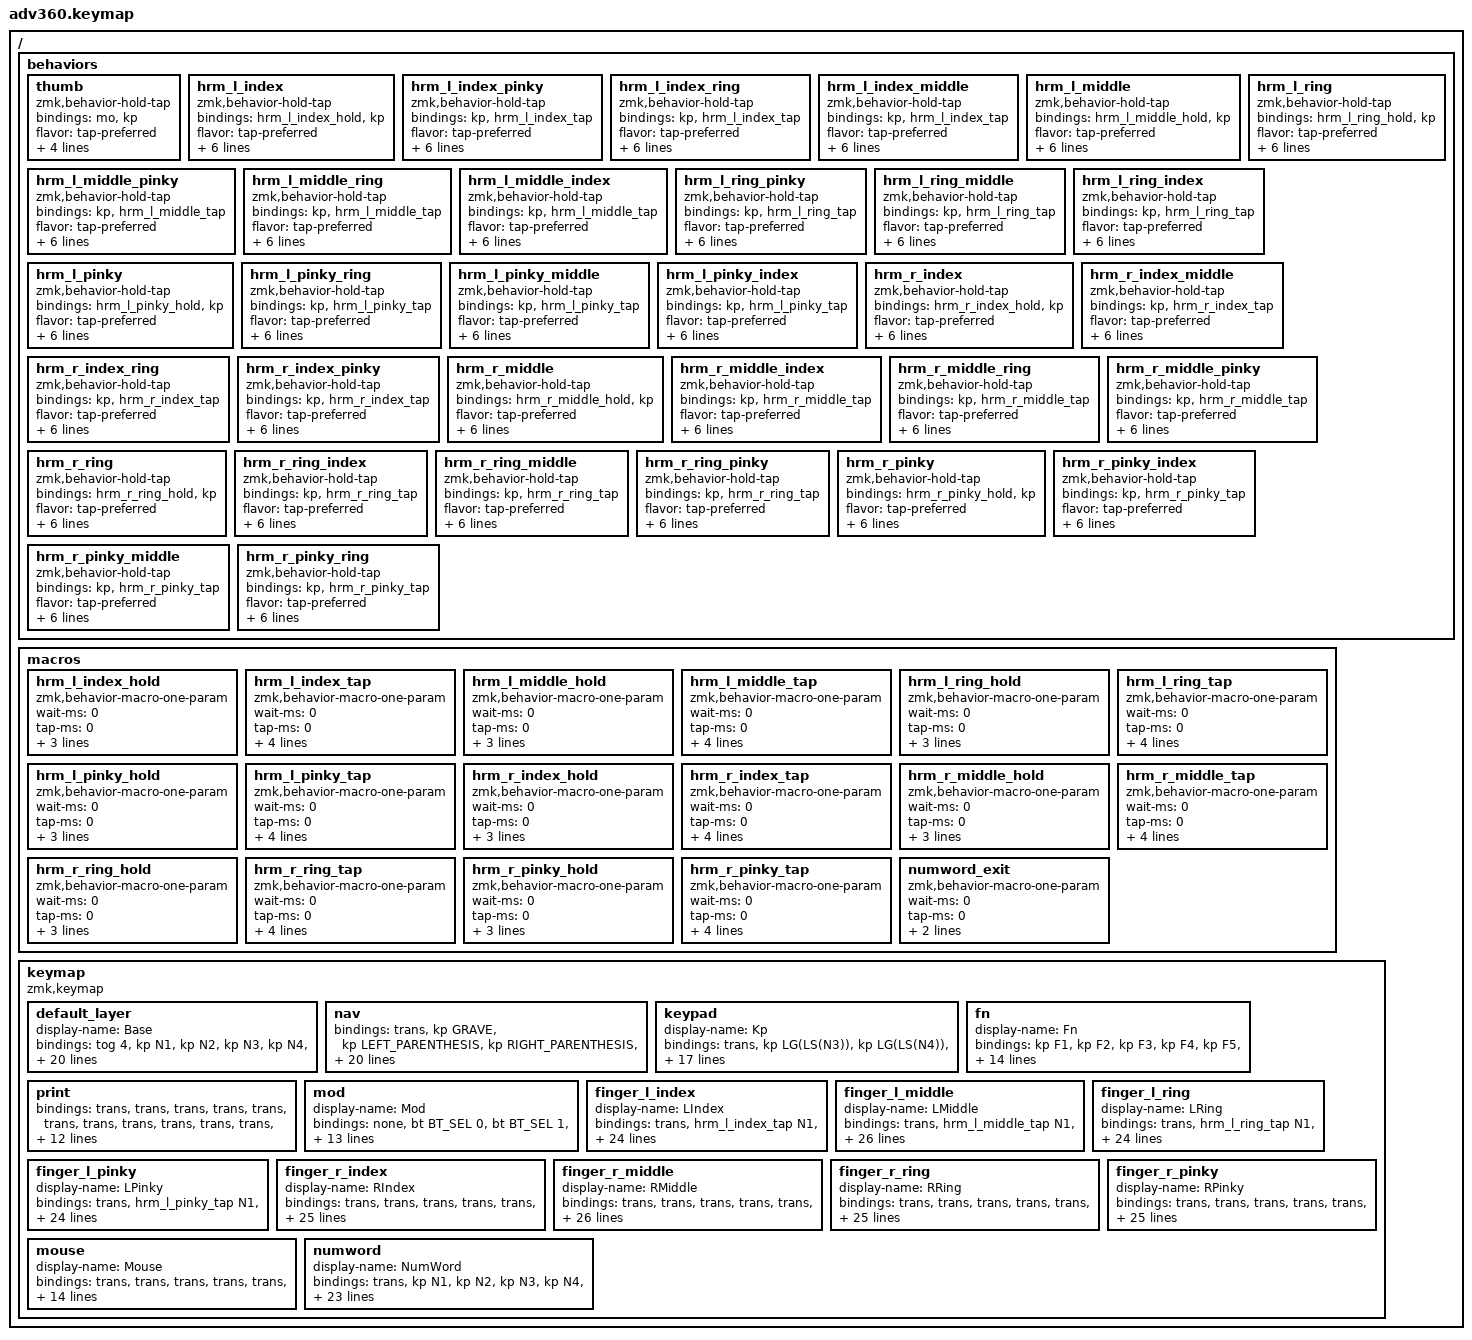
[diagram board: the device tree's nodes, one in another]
#include <dt-bindings/zmk/stp.h>
#include <behaviors.dtsi>
#include <dt-bindings/zmk/backlight.h>
#include <dt-bindings/zmk/bt.h>
#include <dt-bindings/zmk/keys.h>
#include <dt-bindings/zmk/pointing.h>
#include <dt-bindings/zmk/rgb.h>

/ {
    behaviors {
        #include "macros.dtsi"
      #include "version.dtsi"

        thumb: thumb {
            compatible = "zmk,behavior-hold-tap";
            #binding-cells = <2>;
            bindings = <&mo>, <&kp>;
            flavor = "tap-preferred";
            tapping-term-ms = <200>;
            quick-tap-ms = <300>;
            require-prior-idle-ms = <150>;
            retro-tap;
        };

        hrm_l_index: hrm_l_index {
            compatible = "zmk,behavior-hold-tap";
            #binding-cells = <2>;
            bindings = <&hrm_l_index_hold>, <&kp>;
            flavor = "tap-preferred";
            tapping-term-ms = <180>;
            quick-tap-ms = <300>;
            require-prior-idle-ms = <150>;
            hold-trigger-on-release;
            hold-trigger-key-positions = <7 8 9 10 11 12 13 21 22 23 24 25 26 27 37 38 39 40 41 42 43 44 45 53 54 55 56 57 58 59 68 69 70 71 72 73 74 75>;
        };

        hrm_l_index_pinky: hrm_l_index_pinky {
            compatible = "zmk,behavior-hold-tap";
            #binding-cells = <2>;
            bindings = <&kp>, <&hrm_l_index_tap>;
            flavor = "tap-preferred";
            tapping-term-ms = <180>;
            quick-tap-ms = <300>;
            require-prior-idle-ms = <150>;
            hold-trigger-on-release;
            hold-trigger-key-positions = <7 8 9 10 11 12 13 21 22 23 24 25 26 27 37 38 39 40 41 42 43 44 45 53 54 55 56 57 58 59 68 69 70 71 72 73 74 75>;
        };

        hrm_l_index_ring: hrm_l_index_ring {
            compatible = "zmk,behavior-hold-tap";
            #binding-cells = <2>;
            bindings = <&kp>, <&hrm_l_index_tap>;
            flavor = "tap-preferred";
            tapping-term-ms = <180>;
            quick-tap-ms = <300>;
            require-prior-idle-ms = <150>;
            hold-trigger-on-release;
            hold-trigger-key-positions = <7 8 9 10 11 12 13 21 22 23 24 25 26 27 37 38 39 40 41 42 43 44 45 53 54 55 56 57 58 59 68 69 70 71 72 73 74 75>;
        };

        hrm_l_index_middle: hrm_l_index_middle {
            compatible = "zmk,behavior-hold-tap";
            #binding-cells = <2>;
            bindings = <&kp>, <&hrm_l_index_tap>;
            flavor = "tap-preferred";
            tapping-term-ms = <180>;
            quick-tap-ms = <300>;
            require-prior-idle-ms = <150>;
            hold-trigger-on-release;
            hold-trigger-key-positions = <7 8 9 10 11 12 13 21 22 23 24 25 26 27 37 38 39 40 41 42 43 44 45 53 54 55 56 57 58 59 68 69 70 71 72 73 74 75>;
        };

        hrm_l_middle: hrm_l_middle {
            compatible = "zmk,behavior-hold-tap";
            #binding-cells = <2>;
            bindings = <&hrm_l_middle_hold>, <&kp>;
            flavor = "tap-preferred";
            tapping-term-ms = <210>;
            quick-tap-ms = <300>;
            require-prior-idle-ms = <150>;
            hold-trigger-on-release;
            hold-trigger-key-positions = <7 8 9 10 11 12 13 21 22 23 24 25 26 27 37 38 39 40 41 42 43 44 45 53 54 55 56 57 58 59 68 69 70 71 72 73 74 75>;
        };

        hrm_l_middle_pinky: hrm_l_middle_pinky {
            compatible = "zmk,behavior-hold-tap";
            #binding-cells = <2>;
            bindings = <&kp>, <&hrm_l_middle_tap>;
            flavor = "tap-preferred";
            tapping-term-ms = <210>;
            quick-tap-ms = <300>;
            require-prior-idle-ms = <150>;
            hold-trigger-on-release;
            hold-trigger-key-positions = <7 8 9 10 11 12 13 21 22 23 24 25 26 27 37 38 39 40 41 42 43 44 45 53 54 55 56 57 58 59 68 69 70 71 72 73 74 75>;
        };

        hrm_l_middle_ring: hrm_l_middle_ring {
            compatible = "zmk,behavior-hold-tap";
            #binding-cells = <2>;
            bindings = <&kp>, <&hrm_l_middle_tap>;
            flavor = "tap-preferred";
            tapping-term-ms = <210>;
            quick-tap-ms = <300>;
            require-prior-idle-ms = <150>;
            hold-trigger-on-release;
            hold-trigger-key-positions = <7 8 9 10 11 12 13 21 22 23 24 25 26 27 37 38 39 40 41 42 43 44 45 53 54 55 56 57 58 59 68 69 70 71 72 73 74 75>;
        };

        hrm_l_middle_index: hrm_l_middle_index {
            compatible = "zmk,behavior-hold-tap";
            #binding-cells = <2>;
            bindings = <&kp>, <&hrm_l_middle_tap>;
            flavor = "tap-preferred";
            tapping-term-ms = <210>;
            quick-tap-ms = <300>;
            require-prior-idle-ms = <150>;
            hold-trigger-on-release;
            hold-trigger-key-positions = <7 8 9 10 11 12 13 21 22 23 24 25 26 27 37 38 39 40 41 42 43 44 45 53 54 55 56 57 58 59 68 69 70 71 72 73 74 75>;
        };

        hrm_l_ring: hrm_l_ring {
            compatible = "zmk,behavior-hold-tap";
            #binding-cells = <2>;
            bindings = <&hrm_l_ring_hold>, <&kp>;
            flavor = "tap-preferred";
            tapping-term-ms = <240>;
            quick-tap-ms = <300>;
            require-prior-idle-ms = <150>;
            hold-trigger-on-release;
            hold-trigger-key-positions = <7 8 9 10 11 12 13 21 22 23 24 25 26 27 37 38 39 40 41 42 43 44 45 53 54 55 56 57 58 59 68 69 70 71 72 73 74 75>;
        };

        hrm_l_ring_pinky: hrm_l_ring_pinky {
            compatible = "zmk,behavior-hold-tap";
            #binding-cells = <2>;
            bindings = <&kp>, <&hrm_l_ring_tap>;
            flavor = "tap-preferred";
            tapping-term-ms = <240>;
            quick-tap-ms = <300>;
            require-prior-idle-ms = <150>;
            hold-trigger-on-release;
            hold-trigger-key-positions = <7 8 9 10 11 12 13 21 22 23 24 25 26 27 37 38 39 40 41 42 43 44 45 53 54 55 56 57 58 59 68 69 70 71 72 73 74 75>;
        };

        hrm_l_ring_middle: hrm_l_ring_middle {
            compatible = "zmk,behavior-hold-tap";
            #binding-cells = <2>;
            bindings = <&kp>, <&hrm_l_ring_tap>;
            flavor = "tap-preferred";
            tapping-term-ms = <240>;
            quick-tap-ms = <300>;
            require-prior-idle-ms = <150>;
            hold-trigger-on-release;
            hold-trigger-key-positions = <7 8 9 10 11 12 13 21 22 23 24 25 26 27 37 38 39 40 41 42 43 44 45 53 54 55 56 57 58 59 68 69 70 71 72 73 74 75>;
        };

        hrm_l_ring_index: hrm_l_ring_index {
            compatible = "zmk,behavior-hold-tap";
            #binding-cells = <2>;
            bindings = <&kp>, <&hrm_l_ring_tap>;
            flavor = "tap-preferred";
            tapping-term-ms = <240>;
            quick-tap-ms = <300>;
            require-prior-idle-ms = <150>;
            hold-trigger-on-release;
            hold-trigger-key-positions = <7 8 9 10 11 12 13 21 22 23 24 25 26 27 37 38 39 40 41 42 43 44 45 53 54 55 56 57 58 59 68 69 70 71 72 73 74 75>;
        };

        hrm_l_pinky: hrm_l_pinky {
            compatible = "zmk,behavior-hold-tap";
            #binding-cells = <2>;
            bindings = <&hrm_l_pinky_hold>, <&kp>;
            flavor = "tap-preferred";
            tapping-term-ms = <270>;
            quick-tap-ms = <300>;
            require-prior-idle-ms = <150>;
            hold-trigger-on-release;
            hold-trigger-key-positions = <7 8 9 10 11 12 13 21 22 23 24 25 26 27 37 38 39 40 41 42 43 44 45 53 54 55 56 57 58 59 68 69 70 71 72 73 74 75>;
        };

        hrm_l_pinky_ring: hrm_l_pinky_ring {
            compatible = "zmk,behavior-hold-tap";
            #binding-cells = <2>;
            bindings = <&kp>, <&hrm_l_pinky_tap>;
            flavor = "tap-preferred";
            tapping-term-ms = <270>;
            quick-tap-ms = <300>;
            require-prior-idle-ms = <150>;
            hold-trigger-on-release;
            hold-trigger-key-positions = <7 8 9 10 11 12 13 21 22 23 24 25 26 27 37 38 39 40 41 42 43 44 45 53 54 55 56 57 58 59 68 69 70 71 72 73 74 75>;
        };

        hrm_l_pinky_middle: hrm_l_pinky_middle {
            compatible = "zmk,behavior-hold-tap";
            #binding-cells = <2>;
            bindings = <&kp>, <&hrm_l_pinky_tap>;
            flavor = "tap-preferred";
            tapping-term-ms = <270>;
            quick-tap-ms = <300>;
            require-prior-idle-ms = <150>;
            hold-trigger-on-release;
            hold-trigger-key-positions = <7 8 9 10 11 12 13 21 22 23 24 25 26 27 37 38 39 40 41 42 43 44 45 53 54 55 56 57 58 59 68 69 70 71 72 73 74 75>;
        };

        hrm_l_pinky_index: hrm_l_pinky_index {
            compatible = "zmk,behavior-hold-tap";
            #binding-cells = <2>;
            bindings = <&kp>, <&hrm_l_pinky_tap>;
            flavor = "tap-preferred";
            tapping-term-ms = <270>;
            quick-tap-ms = <300>;
            require-prior-idle-ms = <150>;
            hold-trigger-on-release;
            hold-trigger-key-positions = <7 8 9 10 11 12 13 21 22 23 24 25 26 27 37 38 39 40 41 42 43 44 45 53 54 55 56 57 58 59 68 69 70 71 72 73 74 75>;
        };

        hrm_r_index: hrm_r_index {
            compatible = "zmk,behavior-hold-tap";
            #binding-cells = <2>;
            bindings = <&hrm_r_index_hold>, <&kp>;
            flavor = "tap-preferred";
            tapping-term-ms = <180>;
            quick-tap-ms = <300>;
            require-prior-idle-ms = <150>;
            hold-trigger-on-release;
            hold-trigger-key-positions = <0 1 2 3 4 5 6 14 15 16 17 18 19 20 28 29 30 31 32 33 34 35 36 46 47 48 49 50 51 52 60 61 62 63 64 65 66 67>;
        };

        hrm_r_index_middle: hrm_r_index_middle {
            compatible = "zmk,behavior-hold-tap";
            #binding-cells = <2>;
            bindings = <&kp>, <&hrm_r_index_tap>;
            flavor = "tap-preferred";
            tapping-term-ms = <180>;
            quick-tap-ms = <300>;
            require-prior-idle-ms = <150>;
            hold-trigger-on-release;
            hold-trigger-key-positions = <0 1 2 3 4 5 6 14 15 16 17 18 19 20 28 29 30 31 32 33 34 35 36 46 47 48 49 50 51 52 60 61 62 63 64 65 66 67>;
        };

        hrm_r_index_ring: hrm_r_index_ring {
            compatible = "zmk,behavior-hold-tap";
            #binding-cells = <2>;
            bindings = <&kp>, <&hrm_r_index_tap>;
            flavor = "tap-preferred";
            tapping-term-ms = <180>;
            quick-tap-ms = <300>;
            require-prior-idle-ms = <150>;
            hold-trigger-on-release;
            hold-trigger-key-positions = <0 1 2 3 4 5 6 14 15 16 17 18 19 20 28 29 30 31 32 33 34 35 36 46 47 48 49 50 51 52 60 61 62 63 64 65 66 67>;
        };

        hrm_r_index_pinky: hrm_r_index_pinky {
            compatible = "zmk,behavior-hold-tap";
            #binding-cells = <2>;
            bindings = <&kp>, <&hrm_r_index_tap>;
            flavor = "tap-preferred";
            tapping-term-ms = <180>;
            quick-tap-ms = <300>;
            require-prior-idle-ms = <150>;
            hold-trigger-on-release;
            hold-trigger-key-positions = <0 1 2 3 4 5 6 14 15 16 17 18 19 20 28 29 30 31 32 33 34 35 36 46 47 48 49 50 51 52 60 61 62 63 64 65 66 67>;
        };

        hrm_r_middle: hrm_r_middle {
            compatible = "zmk,behavior-hold-tap";
            #binding-cells = <2>;
            bindings = <&hrm_r_middle_hold>, <&kp>;
            flavor = "tap-preferred";
            tapping-term-ms = <210>;
            quick-tap-ms = <300>;
            require-prior-idle-ms = <150>;
            hold-trigger-on-release;
            hold-trigger-key-positions = <0 1 2 3 4 5 6 14 15 16 17 18 19 20 28 29 30 31 32 33 34 35 36 46 47 48 49 50 51 52 60 61 62 63 64 65 66 67>;
        };

        hrm_r_middle_index: hrm_r_middle_index {
            compatible = "zmk,behavior-hold-tap";
            #binding-cells = <2>;
            bindings = <&kp>, <&hrm_r_middle_tap>;
            flavor = "tap-preferred";
            tapping-term-ms = <210>;
            quick-tap-ms = <300>;
            require-prior-idle-ms = <150>;
            hold-trigger-on-release;
            hold-trigger-key-positions = <0 1 2 3 4 5 6 14 15 16 17 18 19 20 28 29 30 31 32 33 34 35 36 46 47 48 49 50 51 52 60 61 62 63 64 65 66 67>;
        };

        hrm_r_middle_ring: hrm_r_middle_ring {
            compatible = "zmk,behavior-hold-tap";
            #binding-cells = <2>;
            bindings = <&kp>, <&hrm_r_middle_tap>;
            flavor = "tap-preferred";
            tapping-term-ms = <210>;
            quick-tap-ms = <300>;
            require-prior-idle-ms = <150>;
            hold-trigger-on-release;
            hold-trigger-key-positions = <0 1 2 3 4 5 6 14 15 16 17 18 19 20 28 29 30 31 32 33 34 35 36 46 47 48 49 50 51 52 60 61 62 63 64 65 66 67>;
        };

        hrm_r_middle_pinky: hrm_r_middle_pinky {
            compatible = "zmk,behavior-hold-tap";
            #binding-cells = <2>;
            bindings = <&kp>, <&hrm_r_middle_tap>;
            flavor = "tap-preferred";
            tapping-term-ms = <210>;
            quick-tap-ms = <300>;
            require-prior-idle-ms = <150>;
            hold-trigger-on-release;
            hold-trigger-key-positions = <0 1 2 3 4 5 6 14 15 16 17 18 19 20 28 29 30 31 32 33 34 35 36 46 47 48 49 50 51 52 60 61 62 63 64 65 66 67>;
        };

        hrm_r_ring: hrm_r_ring {
            compatible = "zmk,behavior-hold-tap";
            #binding-cells = <2>;
            bindings = <&hrm_r_ring_hold>, <&kp>;
            flavor = "tap-preferred";
            tapping-term-ms = <240>;
            quick-tap-ms = <300>;
            require-prior-idle-ms = <150>;
            hold-trigger-on-release;
            hold-trigger-key-positions = <0 1 2 3 4 5 6 14 15 16 17 18 19 20 28 29 30 31 32 33 34 35 36 46 47 48 49 50 51 52 60 61 62 63 64 65 66 67>;
        };

        hrm_r_ring_index: hrm_r_ring_index {
            compatible = "zmk,behavior-hold-tap";
            #binding-cells = <2>;
            bindings = <&kp>, <&hrm_r_ring_tap>;
            flavor = "tap-preferred";
            tapping-term-ms = <240>;
            quick-tap-ms = <300>;
            require-prior-idle-ms = <150>;
            hold-trigger-on-release;
            hold-trigger-key-positions = <0 1 2 3 4 5 6 14 15 16 17 18 19 20 28 29 30 31 32 33 34 35 36 46 47 48 49 50 51 52 60 61 62 63 64 65 66 67>;
        };

        hrm_r_ring_middle: hrm_r_ring_middle {
            compatible = "zmk,behavior-hold-tap";
            #binding-cells = <2>;
            bindings = <&kp>, <&hrm_r_ring_tap>;
            flavor = "tap-preferred";
            tapping-term-ms = <240>;
            quick-tap-ms = <300>;
            require-prior-idle-ms = <150>;
            hold-trigger-on-release;
            hold-trigger-key-positions = <0 1 2 3 4 5 6 14 15 16 17 18 19 20 28 29 30 31 32 33 34 35 36 46 47 48 49 50 51 52 60 61 62 63 64 65 66 67>;
        };

        hrm_r_ring_pinky: hrm_r_ring_pinky {
            compatible = "zmk,behavior-hold-tap";
            #binding-cells = <2>;
            bindings = <&kp>, <&hrm_r_ring_tap>;
            flavor = "tap-preferred";
            tapping-term-ms = <240>;
            quick-tap-ms = <300>;
            require-prior-idle-ms = <150>;
            hold-trigger-on-release;
            hold-trigger-key-positions = <0 1 2 3 4 5 6 14 15 16 17 18 19 20 28 29 30 31 32 33 34 35 36 46 47 48 49 50 51 52 60 61 62 63 64 65 66 67>;
        };

        hrm_r_pinky: hrm_r_pinky {
            compatible = "zmk,behavior-hold-tap";
            #binding-cells = <2>;
            bindings = <&hrm_r_pinky_hold>, <&kp>;
            flavor = "tap-preferred";
            tapping-term-ms = <270>;
            quick-tap-ms = <300>;
            require-prior-idle-ms = <150>;
            hold-trigger-on-release;
            hold-trigger-key-positions = <0 1 2 3 4 5 6 14 15 16 17 18 19 20 28 29 30 31 32 33 34 35 36 46 47 48 49 50 51 52 60 61 62 63 64 65 66 67>;
        };

        hrm_r_pinky_index: hrm_r_pinky_index {
            compatible = "zmk,behavior-hold-tap";
            #binding-cells = <2>;
            bindings = <&kp>, <&hrm_r_pinky_tap>;
            flavor = "tap-preferred";
            tapping-term-ms = <270>;
            quick-tap-ms = <300>;
            require-prior-idle-ms = <150>;
            hold-trigger-on-release;
            hold-trigger-key-positions = <0 1 2 3 4 5 6 14 15 16 17 18 19 20 28 29 30 31 32 33 34 35 36 46 47 48 49 50 51 52 60 61 62 63 64 65 66 67>;
        };

        hrm_r_pinky_middle: hrm_r_pinky_middle {
            compatible = "zmk,behavior-hold-tap";
            #binding-cells = <2>;
            bindings = <&kp>, <&hrm_r_pinky_tap>;
            flavor = "tap-preferred";
            tapping-term-ms = <270>;
            quick-tap-ms = <300>;
            require-prior-idle-ms = <150>;
            hold-trigger-on-release;
            hold-trigger-key-positions = <0 1 2 3 4 5 6 14 15 16 17 18 19 20 28 29 30 31 32 33 34 35 36 46 47 48 49 50 51 52 60 61 62 63 64 65 66 67>;
        };

        hrm_r_pinky_ring: hrm_r_pinky_ring {
            compatible = "zmk,behavior-hold-tap";
            #binding-cells = <2>;
            bindings = <&kp>, <&hrm_r_pinky_tap>;
            flavor = "tap-preferred";
            tapping-term-ms = <270>;
            quick-tap-ms = <300>;
            require-prior-idle-ms = <150>;
            hold-trigger-on-release;
            hold-trigger-key-positions = <0 1 2 3 4 5 6 14 15 16 17 18 19 20 28 29 30 31 32 33 34 35 36 46 47 48 49 50 51 52 60 61 62 63 64 65 66 67>;
        };
    };

    macros {
        hrm_l_index_hold: hrm_l_index_hold {
            compatible = "zmk,behavior-macro-one-param";
            #binding-cells = <1>;
            wait-ms = <0>;
            tap-ms = <0>;
            bindings = <&macro_press>, <&macro_param_1to1>, <&kp A>, <&mo 6>, <&macro_pause_for_release>, <&macro_release>, <&macro_param_1to1>, <&kp A>, <&mo 6>;
        };

        hrm_l_index_tap: hrm_l_index_tap {
            compatible = "zmk,behavior-macro-one-param";
            #binding-cells = <1>;
            wait-ms = <0>;
            tap-ms = <0>;
            bindings = <&macro_release>, <&kp LSHFT>, <&kp RSHFT>, <&kp LALT>, <&kp RALT>, <&kp LCTRL>, <&kp RCTRL>, <&kp LGUI>, <&kp RGUI>, <&macro_tap>, <&kp E>, <&macro_tap>, <&macro_param_1to1>, <&kp A>;
        };

        hrm_l_middle_hold: hrm_l_middle_hold {
            compatible = "zmk,behavior-macro-one-param";
            #binding-cells = <1>;
            wait-ms = <0>;
            tap-ms = <0>;
            bindings = <&macro_press>, <&macro_param_1to1>, <&kp A>, <&mo 7>, <&macro_pause_for_release>, <&macro_release>, <&macro_param_1to1>, <&kp A>, <&mo 7>;
        };

        hrm_l_middle_tap: hrm_l_middle_tap {
            compatible = "zmk,behavior-macro-one-param";
            #binding-cells = <1>;
            wait-ms = <0>;
            tap-ms = <0>;
            bindings = <&macro_release>, <&kp LSHFT>, <&kp RSHFT>, <&kp LALT>, <&kp RALT>, <&kp LCTRL>, <&kp RCTRL>, <&kp LGUI>, <&kp RGUI>, <&macro_tap>, <&kp A>, <&macro_tap>, <&macro_param_1to1>, <&kp A>;
        };

        hrm_l_ring_hold: hrm_l_ring_hold {
            compatible = "zmk,behavior-macro-one-param";
            #binding-cells = <1>;
            wait-ms = <0>;
            tap-ms = <0>;
            bindings = <&macro_press>, <&macro_param_1to1>, <&kp A>, <&mo 8>, <&macro_pause_for_release>, <&macro_release>, <&macro_param_1to1>, <&kp A>, <&mo 8>;
        };

        hrm_l_ring_tap: hrm_l_ring_tap {
            compatible = "zmk,behavior-macro-one-param";
            #binding-cells = <1>;
            wait-ms = <0>;
            tap-ms = <0>;
            bindings = <&macro_release>, <&kp LSHFT>, <&kp RSHFT>, <&kp LALT>, <&kp RALT>, <&kp LCTRL>, <&kp RCTRL>, <&kp LGUI>, <&kp RGUI>, <&macro_tap>, <&kp I>, <&macro_tap>, <&macro_param_1to1>, <&kp A>;
        };

        hrm_l_pinky_hold: hrm_l_pinky_hold {
            compatible = "zmk,behavior-macro-one-param";
            #binding-cells = <1>;
            wait-ms = <0>;
            tap-ms = <0>;
            bindings = <&macro_press>, <&macro_param_1to1>, <&kp A>, <&mo 9>, <&macro_pause_for_release>, <&macro_release>, <&macro_param_1to1>, <&kp A>, <&mo 9>;
        };

        hrm_l_pinky_tap: hrm_l_pinky_tap {
            compatible = "zmk,behavior-macro-one-param";
            #binding-cells = <1>;
            wait-ms = <0>;
            tap-ms = <0>;
            bindings = <&macro_release>, <&kp LSHFT>, <&kp RSHFT>, <&kp LALT>, <&kp RALT>, <&kp LCTRL>, <&kp RCTRL>, <&kp LGUI>, <&kp RGUI>, <&macro_tap>, <&kp C>, <&macro_tap>, <&macro_param_1to1>, <&kp A>;
        };

        hrm_r_index_hold: hrm_r_index_hold {
            compatible = "zmk,behavior-macro-one-param";
            #binding-cells = <1>;
            wait-ms = <0>;
            tap-ms = <0>;
            bindings = <&macro_press>, <&macro_param_1to1>, <&kp A>, <&mo 10>, <&macro_pause_for_release>, <&macro_release>, <&macro_param_1to1>, <&kp A>, <&mo 10>;
        };

        hrm_r_index_tap: hrm_r_index_tap {
            compatible = "zmk,behavior-macro-one-param";
            #binding-cells = <1>;
            wait-ms = <0>;
            tap-ms = <0>;
            bindings = <&macro_release>, <&kp LSHFT>, <&kp RSHFT>, <&kp LALT>, <&kp RALT>, <&kp LCTRL>, <&kp RCTRL>, <&kp LGUI>, <&kp RGUI>, <&macro_tap>, <&kp H>, <&macro_tap>, <&macro_param_1to1>, <&kp A>;
        };

        hrm_r_middle_hold: hrm_r_middle_hold {
            compatible = "zmk,behavior-macro-one-param";
            #binding-cells = <1>;
            wait-ms = <0>;
            tap-ms = <0>;
            bindings = <&macro_press>, <&macro_param_1to1>, <&kp A>, <&mo 11>, <&macro_pause_for_release>, <&macro_release>, <&macro_param_1to1>, <&kp A>, <&mo 11>;
        };

        hrm_r_middle_tap: hrm_r_middle_tap {
            compatible = "zmk,behavior-macro-one-param";
            #binding-cells = <1>;
            wait-ms = <0>;
            tap-ms = <0>;
            bindings = <&macro_release>, <&kp LSHFT>, <&kp RSHFT>, <&kp LALT>, <&kp RALT>, <&kp LCTRL>, <&kp RCTRL>, <&kp LGUI>, <&kp RGUI>, <&macro_tap>, <&kp T>, <&macro_tap>, <&macro_param_1to1>, <&kp A>;
        };

        hrm_r_ring_hold: hrm_r_ring_hold {
            compatible = "zmk,behavior-macro-one-param";
            #binding-cells = <1>;
            wait-ms = <0>;
            tap-ms = <0>;
            bindings = <&macro_press>, <&macro_param_1to1>, <&kp A>, <&mo 12>, <&macro_pause_for_release>, <&macro_release>, <&macro_param_1to1>, <&kp A>, <&mo 12>;
        };

        hrm_r_ring_tap: hrm_r_ring_tap {
            compatible = "zmk,behavior-macro-one-param";
            #binding-cells = <1>;
            wait-ms = <0>;
            tap-ms = <0>;
            bindings = <&macro_release>, <&kp LSHFT>, <&kp RSHFT>, <&kp LALT>, <&kp RALT>, <&kp LCTRL>, <&kp RCTRL>, <&kp LGUI>, <&kp RGUI>, <&macro_tap>, <&kp N>, <&macro_tap>, <&macro_param_1to1>, <&kp A>;
        };

        hrm_r_pinky_hold: hrm_r_pinky_hold {
            compatible = "zmk,behavior-macro-one-param";
            #binding-cells = <1>;
            wait-ms = <0>;
            tap-ms = <0>;
            bindings = <&macro_press>, <&macro_param_1to1>, <&kp A>, <&mo 13>, <&macro_pause_for_release>, <&macro_release>, <&macro_param_1to1>, <&kp A>, <&mo 13>;
        };

        hrm_r_pinky_tap: hrm_r_pinky_tap {
            compatible = "zmk,behavior-macro-one-param";
            #binding-cells = <1>;
            wait-ms = <0>;
            tap-ms = <0>;
            bindings = <&macro_release>, <&kp LSHFT>, <&kp RSHFT>, <&kp LALT>, <&kp RALT>, <&kp LCTRL>, <&kp RCTRL>, <&kp LGUI>, <&kp RGUI>, <&macro_tap>, <&kp S>, <&macro_tap>, <&macro_param_1to1>, <&kp A>;
        };

        numword_exit: numword_exit {
            compatible = "zmk,behavior-macro-one-param";
            #binding-cells = <1>;
            wait-ms = <0>;
            tap-ms = <0>;
            bindings = <&macro_tap>, <&macro_param_1to1>, <&kp A>, <&macro_tap>, <&tog 15>;
        };
    };

    keymap {
        compatible = "zmk,keymap";

        default_layer {
            display-name = "Base";
            bindings = <
&tog 4                      &kp N1                      &kp N2                      &kp N3                      &kp N4                      &kp N5                      &tog 15                     &mo 5                       &kp N6                      &kp N7                      &kp N8                      &kp N9                      &kp N0                      &kp LC(C)
&gresc                      &kp Q                       &kp Y                       &kp O                       &kp U                       &kp EQUAL                   &tog 14                     &none                       &kp X                       &kp L                       &kp D                       &kp P                       &kp Z                       &kp ENTER
&kp B                       &hrm_l_pinky LEFT_SHIFT C   &hrm_l_ring LCTRL I         &hrm_l_middle LEFT_ALT A    &hrm_l_index LEFT_GUI E     &kp MINUS                   &mo 14                      &sk LS(LA(LC(LEFT_GUI)))    &sk LEFT_GUI                &kp DELETE                  &kp SPACE                   &none                       &kp K                       &hrm_r_index RIGHT_GUI H    &hrm_r_middle RIGHT_ALT T   &hrm_r_ring RCTRL N         &hrm_r_pinky RIGHT_SHIFT S  &kp W
&sk LSHFT                   &kp APOS                    &kp COMMA                   &kp DOT                     &kp SEMI                    &kp FSLH                    &kp ENTER                   &kp ESCAPE                  &kp J                       &kp M                       &kp G                       &kp F                       &kp V                       &sk RSHFT
&mo 3                       &kp AMPS                    &kp GRAVE                   &kp BACKSLASH               &kp PLUS                    &thumb 1 SPACE              &thumb 2 TAB                &sk LS(LA(LCTRL))           &kp ENTER                   &thumb 2 BSPC               &thumb 1 R                  &kp LEFT                    &kp DOWN                    &kp UP                      &kp RIGHT                   &mo 3
            >;
        };

        nav {
            bindings = <
&trans           &kp GRAVE         &kp LEFT_PARENTHESIS  &kp RIGHT_PARENTHESIS  &kp SEMICOLON      &kp COMMA     &trans                                                    &trans  &trans    &trans             &trans                &trans                 &trans         &trans
&kp EXCLAMATION  &kp LEFT_BRACKET  &kp LEFT_BRACE        &kp RIGHT_BRACE        &kp RIGHT_BRACKET  &kp QUESTION  &trans                                                    &trans  &trans    &kp RIGHT          &trans                &trans                 &trans         &trans
&kp HASH         &kp CARET         &kp EQUAL             &kp UNDERSCORE         &kp DOLLAR         &kp ASTERISK  &trans       &caps_word  &trans           &trans  &trans  &trans  &kp UP    &kp LEFT           &kp LEFT_PARENTHESIS  &kp RIGHT_PARENTHESIS  &trans         &trans
&kp TILDE        &kp LESS_THAN     &kp PIPE              &kp MINUS              &kp GREATER_THAN   &kp SLASH                              &kp PERIOD       &trans                  &kp DOWN  &kp DOUBLE_QUOTES  &kp SINGLE_QUOTE      &kp GRAVE              &kp BACKSLASH  &trans
&trans           &kp AMPERSAND     &kp SINGLE_QUOTE      &kp DOUBLE_QUOTES      &kp PLUS                         &kp PERCENT  &kp COLON   &kp AT_SIGN      &trans  &trans  &trans            &trans             &trans                &trans                 &trans         &trans
            >;

            label = "Nav";
        };

        keypad {
            display-name = "Kp";
            bindings = <
&trans              &kp LG(LS(N3))      &kp LG(LS(N4))      &kp LC(LG(LS(N4)))  &kp LG(LS(N5))      &trans              &trans              &trans              &trans              &kp KP_NUM          &kp KP_EQUAL        &kp KP_DIVIDE       &kp KP_MULTIPLY     &trans
&kp LG(GRAVE)       &kp LG(W)           &kp LG(LS(LBKT))    &kp LG(LS(RBKT))    &kp LG(T)           &kp LG(F)           &none               &none               &trans              &kp KP_N7           &kp KP_N8           &kp KP_N9           &kp KP_MINUS        &trans
&kp LG(A)           &trans              &trans              &trans              &trans              &kp LG(S)           &none               &kp LCTRL           &kp LALT            &kp LGUI            &kp RCTRL           &none               &trans              &kp KP_N4           &kp KP_N5           &kp KP_N6           &kp KP_PLUS         &trans
&trans              &kp LG(Z)           &kp LG(X)           &kp LG(C)           &kp LG(V)           &kp LG(LS(Z))       &kp HOME            &kp PG_UP           &trans              &kp KP_N1           &kp KP_N2           &kp KP_N3           &kp KP_ENTER        &trans
&trans              &trans              &kp CAPS            &kp LEFT            &kp RIGHT           &kp BSPC            &kp DEL             &kp END             &kp PG_DN           &kp ENTER           &kp KP_N0           &kp UP              &kp DOWN            &kp KP_DOT          &trans              &trans
            >;
        };

        fn {
            display-name = "Fn";
            bindings = <
&kp F1  &kp F2  &kp F3  &kp F4  &kp F5  &kp F6  &none                                       &none   &kp F7             &kp F8      &kp F9             &kp F10          &kp F11     &kp F12
&trans  &trans  &trans  &trans  &trans  &trans  &none                                       &none   &trans             &kp C_NEXT  &trans             &kp C_PP         &trans      &trans
&trans  &trans  &trans  &trans  &trans  &trans  &none   &trans  &trans      &trans  &trans  &none   &kp C_VOLUME_UP    &kp C_PREV  &trans             &trans           &trans      &trans
&trans  &trans  &trans  &trans  &trans  &trans                  &trans      &trans                  &kp C_VOLUME_DOWN  &kp K_MUTE  &trans             &trans           &trans      &trans
&trans  &trans  &trans  &trans  &trans          &trans  &trans  &trans      &trans  &trans  &trans                     &kp C_PREV  &kp C_VOLUME_DOWN  &kp C_VOLUME_UP  &kp C_NEXT  &trans
            >;
        };

        print {
            bindings = <
&trans  &trans  &trans  &trans  &trans  &trans  &trans                                         &trans  &trans  &trans  &trans  &trans  &trans  &trans
&trans  &trans  &trans  &trans  &trans  &trans  &trans                                         &trans  &trans  &trans  &trans  &trans  &trans  &trans
&trans  &kp C   &kp I   &kp A   &kp E   &trans  &trans  &trans  &trans         &trans  &trans  &trans  &trans  &kp H   &kp T   &kp N   &kp S   &trans
&trans  &trans  &trans  &trans  &trans  &trans                  &kp ENTER      &trans                  &trans  &trans  &trans  &trans  &trans  &trans
&trans  &trans  &trans  &trans  &trans          &trans  &trans  &trans         &trans  &trans  &kp R           &trans  &trans  &trans  &trans  &trans
            >;

            label = "Yellow";
        };

        mod {
            display-name = "Mod";
            bindings = <
&none           &bt BT_SEL 0  &bt BT_SEL 1  &bt BT_SEL 2  &bt BT_SEL 3  &bt BT_SEL 4  &none                                                  &trans           &none  &none       &none       &none  &none  &none
&none           &none         &none         &none         &none         &none         &bootloader                                            &bootloader      &none  &none       &none       &none  &none  &none
&studio_unlock  &none         &none         &none         &none         &none         &none        &none  &none      &bt BT_CLR  &none       &stp STP_BAT     &none  &none       &none       &none  &none  &none
&none           &none         &none         &none         &macro_ver    &none                             &none      &none                                    &none  &none       &none       &none  &none  &none
&none           &none         &none         &none         &none                       &none        &none  &none      &none       &bl BL_TOG  &rgb_ug RGB_TOG         &bl BL_INC  &bl BL_DEC  &none  &none  &none
            >;
        };

        finger_l_index {
            display-name = "LIndex";
            bindings = <
                &trans                           &hrm_l_index_tap N1              &hrm_l_index_tap N2              &hrm_l_index_tap N3              &hrm_l_index_tap N4              &hrm_l_index_tap N5              &trans                           &trans                           &trans                           &trans                           &trans                           &trans                           &trans                           &trans
                &trans                           &hrm_l_index_tap Q               &hrm_l_index_tap Y               &hrm_l_index_tap O               &hrm_l_index_tap U               &hrm_l_index_tap EQUAL           &trans                           &trans                           &trans                           &trans                           &trans                           &trans                           &trans                           &trans
                &hrm_l_index_tap B               &hrm_l_index_pinky LEFT_SHIFT C  &hrm_l_index_ring LCTRL I        &hrm_l_index_middle LEFT_ALT A   &none                            &hrm_l_index_tap MINUS           &trans                           &trans                           &trans                           &trans                           &trans                           &trans                           &trans                           &trans                           &trans                           &trans                           &trans                           &trans
                &trans                           &hrm_l_index_tap APOS            &hrm_l_index_tap COMMA           &hrm_l_index_tap DOT             &hrm_l_index_tap SEMI            &hrm_l_index_tap FSLH            &hrm_l_index_tap ENTER           &trans                           &trans                           &trans                           &trans                           &trans                           &trans                           &trans
                &trans                           &hrm_l_index_tap AMPS            &hrm_l_index_tap GRAVE           &hrm_l_index_tap BACKSLASH       &hrm_l_index_tap PLUS            &mo 1                            &mo 2                            &trans                           &trans                           &trans                           &trans                           &trans                           &trans                           &trans                           &trans                           &trans
            >;
        };

        finger_l_middle {
            display-name = "LMiddle";
            bindings = <
                &trans                            &hrm_l_middle_tap N1              &hrm_l_middle_tap N2              &hrm_l_middle_tap N3              &hrm_l_middle_tap N4              &hrm_l_middle_tap N5              &trans                            &trans                            &trans                            &trans                            &trans                            &trans                            &trans                            &trans
                &trans                            &hrm_l_middle_tap Q               &hrm_l_middle_tap Y               &hrm_l_middle_tap O               &hrm_l_middle_tap U               &hrm_l_middle_tap EQUAL           &trans                            &trans                            &trans                            &trans                            &trans                            &trans                            &trans                            &trans
                &hrm_l_middle_tap B               &hrm_l_middle_pinky LEFT_SHIFT C  &hrm_l_middle_ring LCTRL I        &none                             &hrm_l_middle_index LEFT_GUI E    &hrm_l_middle_tap MINUS           &trans                            &trans                            &trans                            &trans                            &trans                            &trans                            &trans                            &trans                            &trans                            &trans                            &trans                            &trans
                &trans                            &hrm_l_middle_tap APOS            &hrm_l_middle_tap COMMA           &hrm_l_middle_tap DOT             &hrm_l_middle_tap SEMI            &hrm_l_middle_tap FSLH            &hrm_l_middle_tap ENTER           &trans                            &trans                            &trans                            &trans                            &trans                            &trans                            &trans
                &trans                            &hrm_l_middle_tap AMPS            &hrm_l_middle_tap GRAVE           &hrm_l_middle_tap BACKSLASH       &hrm_l_middle_tap PLUS            &mo 1                             &mo 2                             &trans                            &trans                            &trans                            &trans                            &trans                            &trans                            &trans                            &trans                            &trans
            >;
        };

        finger_l_ring {
            display-name = "LRing";
            bindings = <
                &trans                          &hrm_l_ring_tap N1              &hrm_l_ring_tap N2              &hrm_l_ring_tap N3              &hrm_l_ring_tap N4              &hrm_l_ring_tap N5              &trans                          &trans                          &trans                          &trans                          &trans                          &trans                          &trans                          &trans
                &trans                          &hrm_l_ring_tap Q               &hrm_l_ring_tap Y               &hrm_l_ring_tap O               &hrm_l_ring_tap U               &hrm_l_ring_tap EQUAL           &trans                          &trans                          &trans                          &trans                          &trans                          &trans                          &trans                          &trans
                &hrm_l_ring_tap B               &hrm_l_ring_pinky LEFT_SHIFT C  &none                           &hrm_l_ring_middle LEFT_ALT A   &hrm_l_ring_index LEFT_GUI E    &hrm_l_ring_tap MINUS           &trans                          &trans                          &trans                          &trans                          &trans                          &trans                          &trans                          &trans                          &trans                          &trans                          &trans                          &trans
                &trans                          &hrm_l_ring_tap APOS            &hrm_l_ring_tap COMMA           &hrm_l_ring_tap DOT             &hrm_l_ring_tap SEMI            &hrm_l_ring_tap FSLH            &hrm_l_ring_tap ENTER           &trans                          &trans                          &trans                          &trans                          &trans                          &trans                          &trans
                &trans                          &hrm_l_ring_tap AMPS            &hrm_l_ring_tap GRAVE           &hrm_l_ring_tap BACKSLASH       &hrm_l_ring_tap PLUS            &mo 1                           &mo 2                           &trans                          &trans                          &trans                          &trans                          &trans                          &trans                          &trans                          &trans                          &trans
            >;
        };

        finger_l_pinky {
            display-name = "LPinky";
            bindings = <
                &trans                          &hrm_l_pinky_tap N1             &hrm_l_pinky_tap N2             &hrm_l_pinky_tap N3             &hrm_l_pinky_tap N4             &hrm_l_pinky_tap N5             &trans                          &trans                          &trans                          &trans                          &trans                          &trans                          &trans                          &trans
                &trans                          &hrm_l_pinky_tap Q              &hrm_l_pinky_tap Y              &hrm_l_pinky_tap O              &hrm_l_pinky_tap U              &hrm_l_pinky_tap EQUAL          &trans                          &trans                          &trans                          &trans                          &trans                          &trans                          &trans                          &trans
                &hrm_l_pinky_tap B              &none                           &hrm_l_pinky_ring LCTRL I       &hrm_l_pinky_middle LEFT_ALT A  &hrm_l_pinky_index LEFT_GUI E   &hrm_l_pinky_tap MINUS          &trans                          &trans                          &trans                          &trans                          &trans                          &trans                          &trans                          &trans                          &trans                          &trans                          &trans                          &trans
                &trans                          &hrm_l_pinky_tap APOS           &hrm_l_pinky_tap COMMA          &hrm_l_pinky_tap DOT            &hrm_l_pinky_tap SEMI           &hrm_l_pinky_tap FSLH           &hrm_l_pinky_tap ENTER          &trans                          &trans                          &trans                          &trans                          &trans                          &trans                          &trans
                &trans                          &hrm_l_pinky_tap AMPS           &hrm_l_pinky_tap GRAVE          &hrm_l_pinky_tap BACKSLASH      &hrm_l_pinky_tap PLUS           &mo 1                           &mo 2                           &trans                          &trans                          &trans                          &trans                          &trans                          &trans                          &trans                          &trans                          &trans
            >;
        };

        finger_r_index {
            display-name = "RIndex";
            bindings = <
                &trans                            &trans                            &trans                            &trans                            &trans                            &trans                            &trans                            &trans                            &hrm_r_index_tap N6               &hrm_r_index_tap N7               &hrm_r_index_tap N8               &hrm_r_index_tap N9               &hrm_r_index_tap N0               &hrm_r_index_tap LC(C)
                &trans                            &trans                            &trans                            &trans                            &trans                            &trans                            &trans                            &trans                            &hrm_r_index_tap X                &hrm_r_index_tap L                &hrm_r_index_tap D                &hrm_r_index_tap P                &hrm_r_index_tap Z                &hrm_r_index_tap ENTER
                &trans                            &trans                            &trans                            &trans                            &trans                            &trans                            &trans                            &trans                            &trans                            &hrm_r_index_tap DELETE           &hrm_r_index_tap SPACE            &trans                            &hrm_r_index_tap K                &none                             &hrm_r_index_middle RIGHT_ALT T   &hrm_r_index_ring RCTRL N         &hrm_r_index_pinky RIGHT_SHIFT S  &hrm_r_index_tap W
                &trans                            &trans                            &trans                            &trans                            &trans                            &trans                            &trans                            &hrm_r_index_tap ESCAPE           &hrm_r_index_tap J                &hrm_r_index_tap M                &hrm_r_index_tap G                &hrm_r_index_tap F                &hrm_r_index_tap V                &trans
                &trans                            &trans                            &trans                            &trans                            &trans                            &trans                            &trans                            &trans                            &hrm_r_index_tap ENTER            &mo 2                             &mo 1                             &hrm_r_index_tap LEFT             &hrm_r_index_tap DOWN             &hrm_r_index_tap UP               &hrm_r_index_tap RIGHT            &trans
            >;
        };

        finger_r_middle {
            display-name = "RMiddle";
            bindings = <
                &trans                             &trans                             &trans                             &trans                             &trans                             &trans                             &trans                             &trans                             &hrm_r_middle_tap N6               &hrm_r_middle_tap N7               &hrm_r_middle_tap N8               &hrm_r_middle_tap N9               &hrm_r_middle_tap N0               &hrm_r_middle_tap LC(C)
                &trans                             &trans                             &trans                             &trans                             &trans                             &trans                             &trans                             &trans                             &hrm_r_middle_tap X                &hrm_r_middle_tap L                &hrm_r_middle_tap D                &hrm_r_middle_tap P                &hrm_r_middle_tap Z                &hrm_r_middle_tap ENTER
                &trans                             &trans                             &trans                             &trans                             &trans                             &trans                             &trans                             &trans                             &trans                             &hrm_r_middle_tap DELETE           &hrm_r_middle_tap SPACE            &trans                             &hrm_r_middle_tap K                &hrm_r_middle_index RIGHT_GUI H    &none                              &hrm_r_middle_ring RCTRL N         &hrm_r_middle_pinky RIGHT_SHIFT S  &hrm_r_middle_tap W
                &trans                             &trans                             &trans                             &trans                             &trans                             &trans                             &trans                             &hrm_r_middle_tap ESCAPE           &hrm_r_middle_tap J                &hrm_r_middle_tap M                &hrm_r_middle_tap G                &hrm_r_middle_tap F                &hrm_r_middle_tap V                &trans
                &trans                             &trans                             &trans                             &trans                             &trans                             &trans                             &trans                             &trans                             &hrm_r_middle_tap ENTER            &mo 2                              &mo 1                              &hrm_r_middle_tap LEFT             &hrm_r_middle_tap DOWN             &hrm_r_middle_tap UP               &hrm_r_middle_tap RIGHT            &trans
            >;
        };

        finger_r_ring {
            display-name = "RRing";
            bindings = <
                &trans                           &trans                           &trans                           &trans                           &trans                           &trans                           &trans                           &trans                           &hrm_r_ring_tap N6               &hrm_r_ring_tap N7               &hrm_r_ring_tap N8               &hrm_r_ring_tap N9               &hrm_r_ring_tap N0               &hrm_r_ring_tap LC(C)
                &trans                           &trans                           &trans                           &trans                           &trans                           &trans                           &trans                           &trans                           &hrm_r_ring_tap X                &hrm_r_ring_tap L                &hrm_r_ring_tap D                &hrm_r_ring_tap P                &hrm_r_ring_tap Z                &hrm_r_ring_tap ENTER
                &trans                           &trans                           &trans                           &trans                           &trans                           &trans                           &trans                           &trans                           &trans                           &hrm_r_ring_tap DELETE           &hrm_r_ring_tap SPACE            &trans                           &hrm_r_ring_tap K                &hrm_r_ring_index RIGHT_GUI H    &hrm_r_ring_middle RIGHT_ALT T   &none                            &hrm_r_ring_pinky RIGHT_SHIFT S  &hrm_r_ring_tap W
                &trans                           &trans                           &trans                           &trans                           &trans                           &trans                           &trans                           &hrm_r_ring_tap ESCAPE           &hrm_r_ring_tap J                &hrm_r_ring_tap M                &hrm_r_ring_tap G                &hrm_r_ring_tap F                &hrm_r_ring_tap V                &trans
                &trans                           &trans                           &trans                           &trans                           &trans                           &trans                           &trans                           &trans                           &hrm_r_ring_tap ENTER            &mo 2                            &mo 1                            &hrm_r_ring_tap LEFT             &hrm_r_ring_tap DOWN             &hrm_r_ring_tap UP               &hrm_r_ring_tap RIGHT            &trans
            >;
        };

        finger_r_pinky {
            display-name = "RPinky";
            bindings = <
                &trans                           &trans                           &trans                           &trans                           &trans                           &trans                           &trans                           &trans                           &hrm_r_pinky_tap N6              &hrm_r_pinky_tap N7              &hrm_r_pinky_tap N8              &hrm_r_pinky_tap N9              &hrm_r_pinky_tap N0              &hrm_r_pinky_tap LC(C)
                &trans                           &trans                           &trans                           &trans                           &trans                           &trans                           &trans                           &trans                           &hrm_r_pinky_tap X               &hrm_r_pinky_tap L               &hrm_r_pinky_tap D               &hrm_r_pinky_tap P               &hrm_r_pinky_tap Z               &hrm_r_pinky_tap ENTER
                &trans                           &trans                           &trans                           &trans                           &trans                           &trans                           &trans                           &trans                           &trans                           &hrm_r_pinky_tap DELETE          &hrm_r_pinky_tap SPACE           &trans                           &hrm_r_pinky_tap K               &hrm_r_pinky_index RIGHT_GUI H   &hrm_r_pinky_middle RIGHT_ALT T  &hrm_r_pinky_ring RCTRL N        &none                            &hrm_r_pinky_tap W
                &trans                           &trans                           &trans                           &trans                           &trans                           &trans                           &trans                           &hrm_r_pinky_tap ESCAPE          &hrm_r_pinky_tap J               &hrm_r_pinky_tap M               &hrm_r_pinky_tap G               &hrm_r_pinky_tap F               &hrm_r_pinky_tap V               &trans
                &trans                           &trans                           &trans                           &trans                           &trans                           &trans                           &trans                           &trans                           &hrm_r_pinky_tap ENTER           &mo 2                            &mo 1                            &hrm_r_pinky_tap LEFT            &hrm_r_pinky_tap DOWN            &hrm_r_pinky_tap UP              &hrm_r_pinky_tap RIGHT           &trans
            >;
        };
        mouse {
            display-name = "Mouse";
            bindings = <
                &trans           &trans           &trans           &trans           &trans           &trans           &trans           &trans           &trans           &trans           &trans           &trans           &trans           &trans
                &trans           &trans           &trans           &trans           &trans           &trans           &trans           &trans           &trans           &mmv MOVE_RIGHT  &msc SCRL_UP     &trans           &trans           &trans
                &trans           &trans           &trans           &trans           &trans           &trans           &trans           &trans           &trans           &trans           &trans           &trans           &mmv MOVE_UP     &mmv MOVE_LEFT   &msc SCRL_LEFT   &msc SCRL_RIGHT  &trans           &trans
                &trans           &trans           &trans           &trans           &trans           &trans           &mkp MCLK        &trans           &mmv MOVE_DOWN   &trans           &msc SCRL_DOWN   &trans           &trans           &trans
                &trans           &trans           &trans           &trans           &trans           &mkp LCLK        &mkp RCLK        &trans           &trans           &trans           &trans           &trans           &trans           &trans           &trans           &trans
            >;
        };

        numword {
            display-name = "NumWord";
            bindings = <
                &trans                   &kp N1                   &kp N2                   &kp N3                   &kp N4                   &kp N5                   &trans                   &trans                   &kp N6                   &kp N7                   &kp EQUAL                &kp FSLH                 &kp STAR                 &numword_exit LC(C)
                &trans                   &numword_exit Q          &numword_exit Y          &numword_exit O          &numword_exit U          &kp EQUAL                &trans                   &trans                   &numword_exit X          &kp N7                   &kp N8                   &kp N9                   &kp MINUS                &numword_exit ENTER
                &numword_exit B          &numword_exit C          &numword_exit I          &numword_exit A          &numword_exit E          &kp MINUS                &trans                   &trans                   &trans                   &kp DELETE               &numword_exit SPACE      &trans                   &numword_exit K          &kp N4                   &kp N5                   &kp N6                   &kp PLUS                 &numword_exit W
                &trans                   &numword_exit APOS       &kp COMMA                &kp DOT                  &numword_exit SEMI       &kp FSLH                 &numword_exit ENTER      &numword_exit ESCAPE     &numword_exit J          &kp N1                   &kp N2                   &kp N3                   &numword_exit V          &trans
                &trans                   &numword_exit AMPS       &numword_exit GRAVE      &numword_exit BACKSLASH  &kp PLUS                 &numword_exit SPACE      &numword_exit TAB        &trans                   &numword_exit ENTER      &kp BSPC                 &kp N0                   &numword_exit LEFT       &numword_exit DOWN       &kp DOT                  &numword_exit RIGHT      &trans
            >;
        };
    };
};
